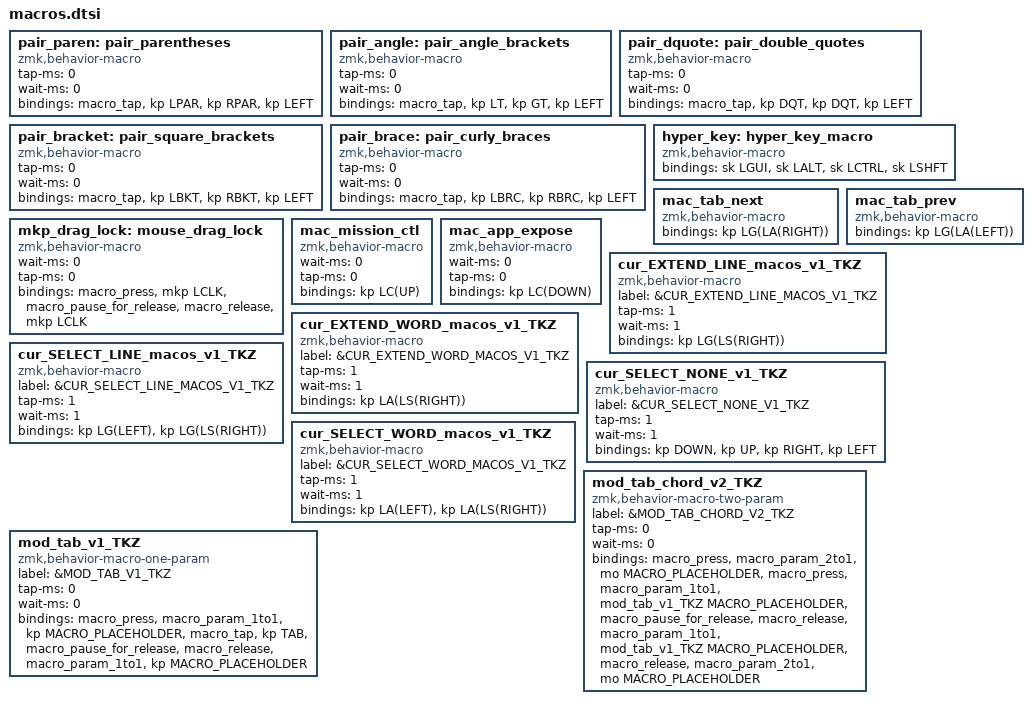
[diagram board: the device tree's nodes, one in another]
/* ------------------------------------------------------------------ */
/*                        Auto-pair macros                            */
/*              Types a pair of characters, cursor in between         */
/* ------------------------------------------------------------------ */

pair_paren: pair_parentheses {
    compatible = "zmk,behavior-macro";
    #binding-cells = <0>;
    tap-ms = <0>;
    wait-ms = <0>;
    bindings = <&macro_tap>
        , <&kp LPAR>
        , <&kp RPAR>
        , <&kp LEFT>;
};

pair_angle: pair_angle_brackets {
    compatible = "zmk,behavior-macro";
    #binding-cells = <0>;
    tap-ms = <0>;
    wait-ms = <0>;
    bindings = <&macro_tap>
        , <&kp LT>
        , <&kp GT>
        , <&kp LEFT>;
};

pair_dquote: pair_double_quotes {
    compatible = "zmk,behavior-macro";
    #binding-cells = <0>;
    tap-ms = <0>;
    wait-ms = <0>;
    bindings = <&macro_tap>
        , <&kp DQT>
        , <&kp DQT>
        , <&kp LEFT>;
};

pair_bracket: pair_square_brackets {
    compatible = "zmk,behavior-macro";
    #binding-cells = <0>;
    tap-ms = <0>;
    wait-ms = <0>;
    bindings = <&macro_tap>
        , <&kp LBKT>
        , <&kp RBKT>
        , <&kp LEFT>;
};

pair_brace: pair_curly_braces {
    compatible = "zmk,behavior-macro";
    #binding-cells = <0>;
    tap-ms = <0>;
    wait-ms = <0>;
    bindings = <&macro_tap>
        , <&kp LBRC>
        , <&kp RBRC>
        , <&kp LEFT>;
};

/* Hyper key macro - ⌘⌃⌥⇧ for Raycast/Alfred */
hyper_key: hyper_key_macro {
compatible = "zmk,behavior-macro";
#binding-cells = <0>;
bindings = <&sk LGUI>, <&sk LALT>, <&sk LCTRL>, <&sk LSHFT>;
};

/* ------------------------------------------------------------------ */
/*                           Tabbing                                  */
/*                                                                    */
/* ------------------------------------------------------------------ */

/* Next Tab (Cmd + Opt + Right) */
mac_tab_next: mac_tab_next {
compatible = "zmk,behavior-macro";
#binding-cells = <0>;
bindings = <&kp LG(LA(RIGHT))>;
};

/* Prev Tab (Cmd + Opt + Left) */
mac_tab_prev: mac_tab_prev {
compatible = "zmk,behavior-macro";
#binding-cells = <0>;
bindings = <&kp LG(LA(LEFT))>;
};

/* ------------------------------------------------------------------ */
/*                      Mouse Macros                                  */
/*      press and hold left click to drag                             */
/* ------------------------------------------------------------------ */

mkp_drag_lock: mouse_drag_lock {
compatible = "zmk,behavior-macro";
#binding-cells = <0>;
wait-ms = <0>;
tap-ms = <0>;
bindings = <&macro_press &mkp LCLK>
        , <&macro_pause_for_release>
        , <&macro_release &mkp LCLK>;
};

/* ------------------------------------------------------------------ */
/*                   Mac Specific Macros                              */
/* ------------------------------------------------------------------ */

/* macOS: Mission Control (Show all windows/desktops) */
mac_mission_ctl: mac_mission_ctl {
compatible = "zmk,behavior-macro";
#binding-cells = <0>;
wait-ms = <0>;
tap-ms = <0>;
bindings = <&kp LC(UP)>;
};

/* macOS: App Expose (Show windows of current app) */
mac_app_expose: mac_app_expose {
compatible = "zmk,behavior-macro";
#binding-cells = <0>;
wait-ms = <0>;
tap-ms = <0>;
bindings = <&kp LC(DOWN)>;
};


/* ------------------------------------------------------------------ */
/*                   Extend text selection                            */
/*               extend text selection macros                         */
/* ------------------------------------------------------------------ */

// Extent Line (seq) - TailorKey
cur_EXTEND_LINE_macos_v1_TKZ: cur_EXTEND_LINE_macos_v1_TKZ {
    label = "&CUR_EXTEND_LINE_MACOS_V1_TKZ";
    compatible = "zmk,behavior-macro";
    #binding-cells = <0>;
    tap-ms = <1>;
    wait-ms = <1>;
    bindings = <&kp LG(LS(RIGHT))>;
};

// Extend Word (seq) - TailorKey
cur_EXTEND_WORD_macos_v1_TKZ: cur_EXTEND_WORD_macos_v1_TKZ {
    label = "&CUR_EXTEND_WORD_MACOS_V1_TKZ";
    compatible = "zmk,behavior-macro";
    #binding-cells = <0>;
    tap-ms = <1>;
    wait-ms = <1>;
    bindings = <&kp LA(LS(RIGHT))>;
};

// Select Line (seq) - TailorKey
cur_SELECT_LINE_macos_v1_TKZ: cur_SELECT_LINE_macos_v1_TKZ {
    label = "&CUR_SELECT_LINE_MACOS_V1_TKZ";
    compatible = "zmk,behavior-macro";
    #binding-cells = <0>;
    tap-ms = <1>;
    wait-ms = <1>;
    bindings = <&kp LG(LEFT)>
        , <&kp LG(LS(RIGHT))>;
};

// Select None (seq) - TailorKey
cur_SELECT_NONE_v1_TKZ: cur_SELECT_NONE_v1_TKZ {
    label = "&CUR_SELECT_NONE_V1_TKZ";
    compatible = "zmk,behavior-macro";
    #binding-cells = <0>;
    tap-ms = <1>;
    wait-ms = <1>;
    bindings = <&kp DOWN>
        , <&kp UP>
        , <&kp RIGHT>
        , <&kp LEFT>;
};

// Select Word (seq) - TailorKey
cur_SELECT_WORD_macos_v1_TKZ: cur_SELECT_WORD_macos_v1_TKZ {
    label = "&CUR_SELECT_WORD_MACOS_V1_TKZ";
    compatible = "zmk,behavior-macro";
    #binding-cells = <0>;
    tap-ms = <1>;
    wait-ms = <1>;
    bindings = <&kp LA(LEFT)>
        , <&kp LA(LS(RIGHT))>;
};

// mod_tab_switcher_chord -  TailorKey
mod_tab_chord_v2_TKZ: mod_tab_chord_v2_TKZ {
    label = "&MOD_TAB_CHORD_V2_TKZ";
    compatible = "zmk,behavior-macro-two-param";
    #binding-cells = <2>;
    tap-ms = <0>;
    wait-ms = <0>;
    bindings = <&macro_press>
        , <&macro_param_2to1>
        , <&mo MACRO_PLACEHOLDER>
        , <&macro_press>
        , <&macro_param_1to1>
        , <&mod_tab_v1_TKZ MACRO_PLACEHOLDER>
        , <&macro_pause_for_release>
        , <&macro_release>
        , <&macro_param_1to1>
        , <&mod_tab_v1_TKZ MACRO_PLACEHOLDER>
        , <&macro_release>
        , <&macro_param_2to1>
        , <&mo MACRO_PLACEHOLDER>;
};

// mod_tab_switcher - TailorKey
mod_tab_v1_TKZ: mod_tab_v1_TKZ {
    label = "&MOD_TAB_V1_TKZ";
    compatible = "zmk,behavior-macro-one-param";
    #binding-cells = <1>;
    tap-ms = <0>;
    wait-ms = <0>;
    bindings = <&macro_press>
        , <&macro_param_1to1>
        , <&kp MACRO_PLACEHOLDER>
        , <&macro_tap>
        , <&kp TAB>
        , <&macro_pause_for_release>
        , <&macro_release>
        , <&macro_param_1to1>
        , <&kp MACRO_PLACEHOLDER>;
};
